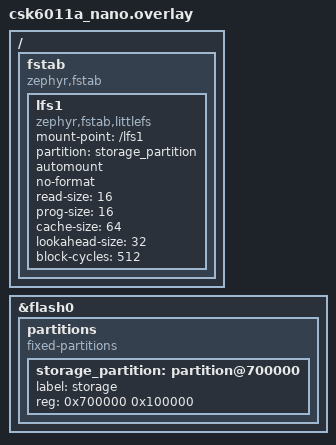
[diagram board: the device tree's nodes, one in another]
/*
 * Copyright (c) 2020 Circuit Dojo LLC
 *
 * SPDX-License-Identifier: Apache-2.0
 */

/delete-node/ &storage_partition;

/ {
	fstab {
		compatible = "zephyr,fstab";
		lfs1: lfs1 {
			compatible = "zephyr,fstab,littlefs";
			mount-point = "/lfs1";
			partition = <&storage_partition>;
			automount ;
			no-format;
			read-size = <16>;
			prog-size = <16>;
			cache-size = <64>;
			lookahead-size = <32>;
			block-cycles = <512>;
		};
	};

};

 
&flash0 {
	partitions {
		compatible = "fixed-partitions";
		#address-cells = <1>;
		#size-cells = <1>;

		/* storage: 1MB for storage */
		storage_partition: partition@700000 {
			label = "storage";
			reg = <0x700000 0x100000>;
		};

	};
};
